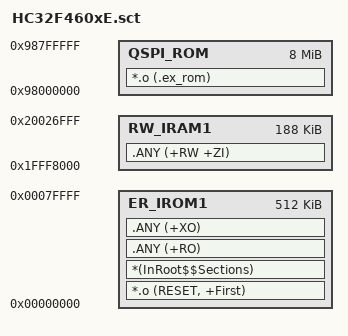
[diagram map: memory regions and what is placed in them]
; ****************************************************************
; Scatter-Loading Description File
; ****************************************************************
LR_IROM1 0x00000000 0x80000  {    ; load region size_region
    ER_IROM1 0x00000000 0x80000  {  ; load address = execution address
        *.o (RESET, +First)
        *(InRoot$$Sections)
        .ANY (+RO)
        .ANY (+XO)
    }
    RW_IRAM1 0x1FFF8000 0x2F000  {  ; RW data
        .ANY (+RW +ZI)
    }
}

EX_QSPI_ROM 0x98000000 0x800000  {
    QSPI_ROM 0x98000000 0x800000  {
        *.o (.ex_rom)
    }
}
